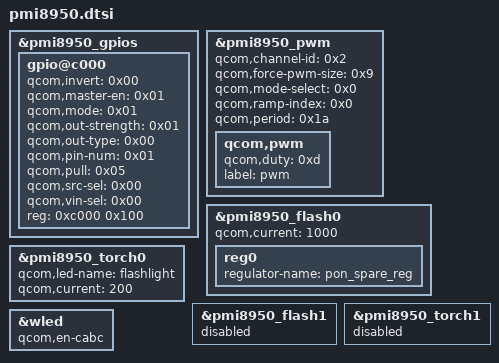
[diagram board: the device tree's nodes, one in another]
&pmi8950_gpios {
	gpio@c000 {
		qcom,invert = < 0x00 >;
		qcom,master-en = < 0x01 >;
		qcom,mode = < 0x01 >;
		qcom,out-strength = < 0x01 >;
		qcom,out-type = < 0x00 >;
		qcom,pin-num = < 0x01 >;
		qcom,pull = < 0x05 >;
		qcom,src-sel = < 0x00 >;
		qcom,vin-sel = < 0x00 >;
		reg = < 0xc000 0x100 >;
		status = "okay";
	};
};

&pmi8950_pwm {
	status = "okay";
	qcom,channel-id = <0x2>;
	qcom,force-pwm-size = <0x9>;
	qcom,mode-select = <0x0>;
	qcom,ramp-index = <0x0>;
	qcom,period = <0x1a>;
	qcom,pwm {
		qcom,duty = <0xd>;
		label = "pwm";
	};
};

&pmi8950_flash0 {
	qcom,current = <1000>;
	reg0 {
		regulator-name = "pon_spare_reg";
	};
};

&pmi8950_torch0 {
	qcom,led-name = "flashlight";
	qcom,current = <200>;
};

&pmi8950_flash1 {
	status = "disabled";
};

&pmi8950_torch1 {
	status = "disabled";
};

&wled {
	/delete-property/ qcom,en-ext-pfet-sc-pro;
	qcom,en-cabc;
};
